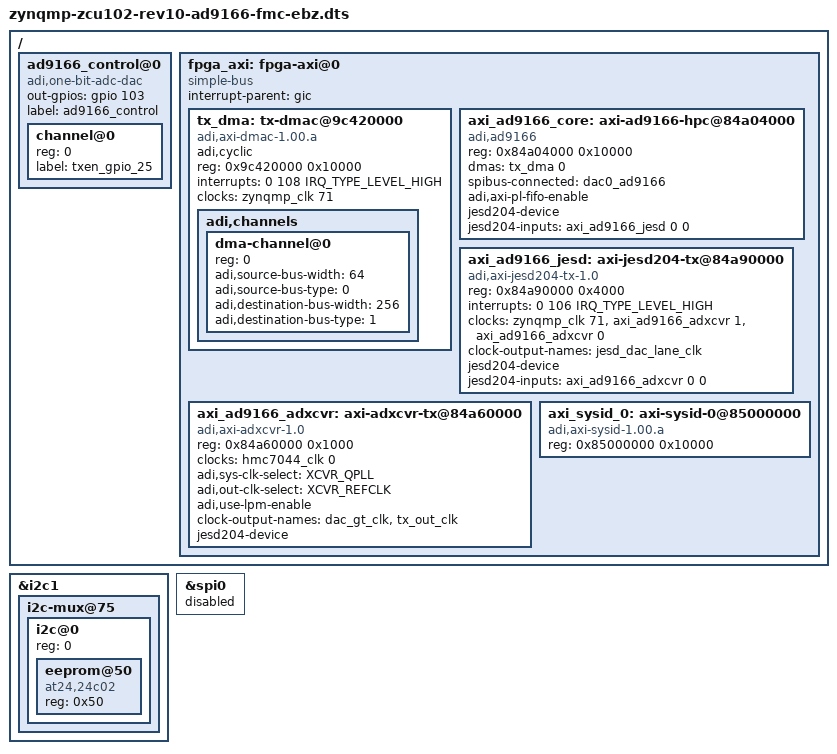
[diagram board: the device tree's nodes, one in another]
// SPDX-License-Identifier: GPL-2.0
/*
 * AD9166-FMC-EBZ on Xilinx ZynqMP ZCU102 Rev 1.0
 *
 * JESD204B Link configuration: L8, M2, F1, S2, NP=16, Interpolation: 2
 *
 * https://analogdevicesinc.github.io/hdl/projects/ad9166_fmc_ebz/index.html
 *
 * hdl_project: <ad9166_fmc_ebz/zcu102>
 * ADI_DAC_DEVICE: <AD9166>
 * ADI_LANE_RATE: <12.5>
 * board_revision: <H>
 *
 * Copyright (C) 2024-2025 Analog Devices Inc.
 */

#include "zynqmp-zcu102-rev1.0.dts"
#include <dt-bindings/interrupt-controller/irq.h>
#include <dt-bindings/jesd204/adxcvr.h>

&i2c1 {
	i2c-mux@75 {
		i2c@0 {
			#address-cells = <1>;
			#size-cells = <0>;
			reg = <0>;

			eeprom@50 {
				compatible = "at24,24c02";
				reg = <0x50>;
			};

		};
	};
};

/ {

	ad9166_control@0 {
		compatible = "adi,one-bit-adc-dac";
		#address-cells = <1>;
		#size-cells = <0>;
		out-gpios = <&gpio 103 0>; // HDL GPIO 25
		label = "ad9166_control";
		channel@0 {
			reg = <0>;
			label = "txen_gpio_25";
		};
	};

	fpga_axi: fpga-axi@0 {
		interrupt-parent = <&gic>;
		compatible = "simple-bus";
		#address-cells = <1>;
		#size-cells = <1>;
		ranges = <0 0 0 0xffffffff>;

		tx_dma: tx-dmac@9c420000 {
			#dma-cells = <1>;
			compatible = "adi,axi-dmac-1.00.a";
			adi,cyclic;
			reg = <0x9c420000 0x10000>;
			interrupts = <0 108 IRQ_TYPE_LEVEL_HIGH>;
			clocks = <&zynqmp_clk 71>;

			adi,channels {
				#size-cells = <0>;
				#address-cells = <1>;

				dma-channel@0 {
					reg = <0>;
					adi,source-bus-width = <64>;
					adi,source-bus-type = <0>;
					adi,destination-bus-width = <256>; // 32 * JESD_L * NUM_OF_LINKS
					adi,destination-bus-type = <1>;
				};
			};
		};

		// transport layer
		axi_ad9166_core: axi-ad9166-hpc@84a04000 {
			compatible = "adi,ad9166";
			reg = <0x84a04000 0x10000>;
			dmas = <&tx_dma 0>;
			dma-names = "tx";
			spibus-connected = <&dac0_ad9166>;
			adi,axi-pl-fifo-enable;
			/* jesd204-fsm support */
			jesd204-device;
			#jesd204-cells = <2>;
			jesd204-inputs = <&axi_ad9166_jesd 0 0>;
		};

		// link layer
		axi_ad9166_jesd: axi-jesd204-tx@84a90000 {
			compatible = "adi,axi-jesd204-tx-1.0";
			reg = <0x84a90000 0x4000>;

			interrupts = <0 106 IRQ_TYPE_LEVEL_HIGH>;

			clocks = <&zynqmp_clk 71>, <&axi_ad9166_adxcvr 1>, <&axi_ad9166_adxcvr 0>;
			clock-names = "s_axi_aclk", "device_clk", "lane_clk";

			#clock-cells = <0>;
			clock-output-names = "jesd_dac_lane_clk";

			/* jesd204-fsm support */
			jesd204-device;
			#jesd204-cells = <2>;
			jesd204-inputs = <&axi_ad9166_adxcvr 0 0>;
		};

		// physical layer
		axi_ad9166_adxcvr: axi-adxcvr-tx@84a60000 {
			compatible = "adi,axi-adxcvr-1.0";
			reg = <0x84a60000 0x1000>;

			clocks = <&hmc7044_clk 0>;
			clock-names = "conv";

			adi,sys-clk-select = <XCVR_QPLL>;
			adi,out-clk-select = <XCVR_REFCLK>;
			adi,use-lpm-enable;

			#clock-cells = <1>;
			clock-output-names = "dac_gt_clk", "tx_out_clk";

			/* jesd204-fsm support */
			jesd204-device;
			#jesd204-cells = <2>;
		};

		axi_sysid_0: axi-sysid-0@85000000 {
			compatible = "adi,axi-sysid-1.00.a";
			reg = <0x85000000 0x10000>;
		};
	};
};

&spi0 {
	status = "disabled";
};

// #define fmc_spi spi0

#include "adi-ad9166-fmc-ebz.dtsi"
